# STM32H745_CM4 register map
File version: 2.5
CPU: CM4 r0p1, little endian, MPU, FPU, 4 interrupt priority bits
Registers are 32-bit, read-write, reset 0x0 unless marked. A register's access mark holds for its fields unless they carry their own. Offsets are from the block's base; [hi:lo] are bit positions; {n}, {i} and the like mark numbered series.

## DELAY_Block_SDMMC1
Base 0x52008000
Same registers: DELAY_Block_SDMMC2 0x48022800, DELAY_Block_QUADSPI 0x52006000
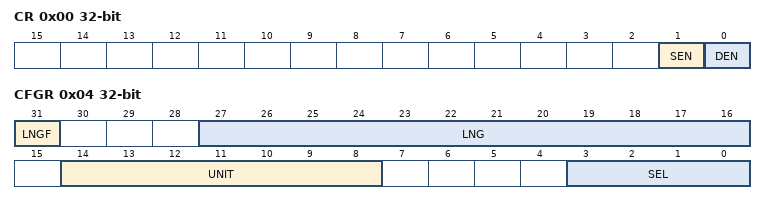
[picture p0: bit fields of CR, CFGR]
0x00 CR — DLYB control register
  [1] SEN — Sampler length enable bit
  [0] DEN — Delay block enable bit
0x04 CFGR — DLYB configuration register
  [31] LNGF — Length valid flag
  [27:16] LNG — Delay line length value
  [14:8] UNIT — Delay Defines the delay of a Unit delay cell
  [3:0] SEL — Select the phase for the Output clock

## DCMI — Digital camera interface
Base 0x48020000
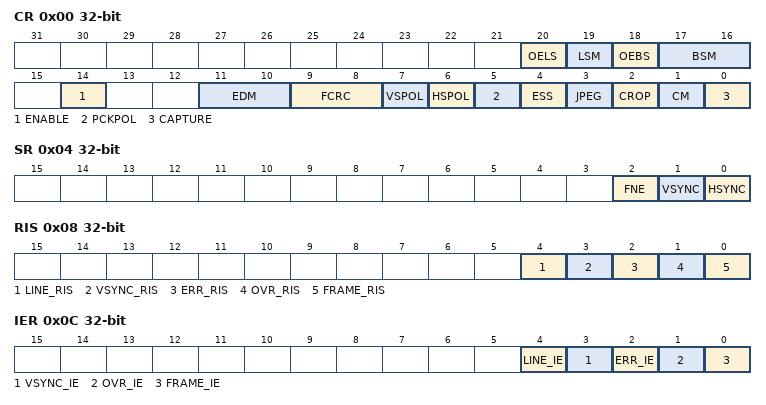
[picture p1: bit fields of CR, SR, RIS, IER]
0x00 CR — control register 1
  [20] OELS — Odd/Even Line Select (Line Select Start)
  [19] LSM — Line Select mode
  [18] OEBS — Odd/Even Byte Select (Byte Select Start)
  [17:16] BSM — Byte Select mode
  [14] ENABLE — DCMI enable
  [11:10] EDM — Extended data mode
  [9:8] FCRC — Frame capture rate control
  [7] VSPOL — Vertical synchronization polarity
  [6] HSPOL — Horizontal synchronization polarity
  [5] PCKPOL — Pixel clock polarity
  [4] ESS — Embedded synchronization select
  [3] JPEG — JPEG format
  [2] CROP — Crop feature
  [1] CM — Capture mode
  [0] CAPTURE — Capture enable
0x04 SR ro — status register
  [2] FNE — FIFO not empty
  [1] VSYNC
  [0] HSYNC
0x08 RIS ro — raw interrupt status register
  [4] LINE_RIS — Line raw interrupt status
  [3] VSYNC_RIS — VSYNC raw interrupt status
  [2] ERR_RIS — Synchronization error raw interrupt status
  [1] OVR_RIS — Overrun raw interrupt status
  [0] FRAME_RIS — Capture complete raw interrupt status
0x0C IER — interrupt enable register
  [4] LINE_IE — Line interrupt enable
  [3] VSYNC_IE — VSYNC interrupt enable
  [2] ERR_IE — Synchronization error interrupt enable
  [1] OVR_IE — Overrun interrupt enable
  [0] FRAME_IE — Capture complete interrupt enable
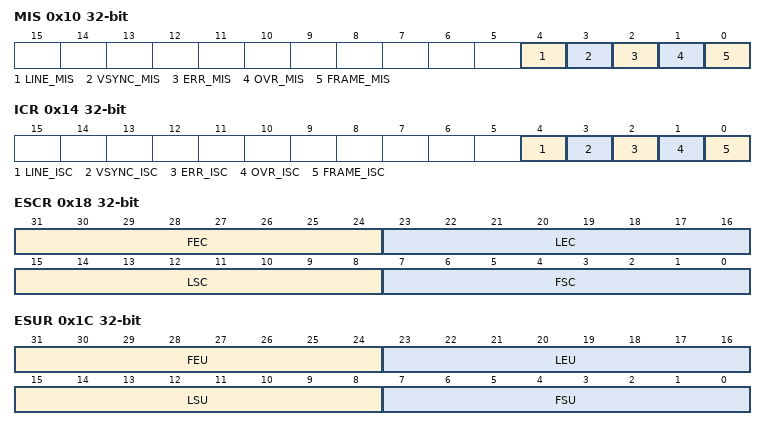
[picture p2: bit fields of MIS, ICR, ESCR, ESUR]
0x10 MIS ro — masked interrupt status register
  [4] LINE_MIS — Line masked interrupt status
  [3] VSYNC_MIS — VSYNC masked interrupt status
  [2] ERR_MIS — Synchronization error masked interrupt status
  [1] OVR_MIS — Overrun masked interrupt status
  [0] FRAME_MIS — Capture complete masked interrupt status
0x14 ICR wo — interrupt clear register
  [4] LINE_ISC — line interrupt status clear
  [3] VSYNC_ISC — Vertical synch interrupt status clear
  [2] ERR_ISC — Synchronization error interrupt status clear
  [1] OVR_ISC — Overrun interrupt status clear
  [0] FRAME_ISC — Capture complete interrupt status clear
0x18 ESCR — embedded synchronization code register
  [31:24] FEC — Frame end delimiter code
  [23:16] LEC — Line end delimiter code
  [15:8] LSC — Line start delimiter code
  [7:0] FSC — Frame start delimiter code
0x1C ESUR — embedded synchronization unmask register
  [31:24] FEU — Frame end delimiter unmask
  [23:16] LEU — Line end delimiter unmask
  [15:8] LSU — Line start delimiter unmask
  [7:0] FSU — Frame start delimiter unmask
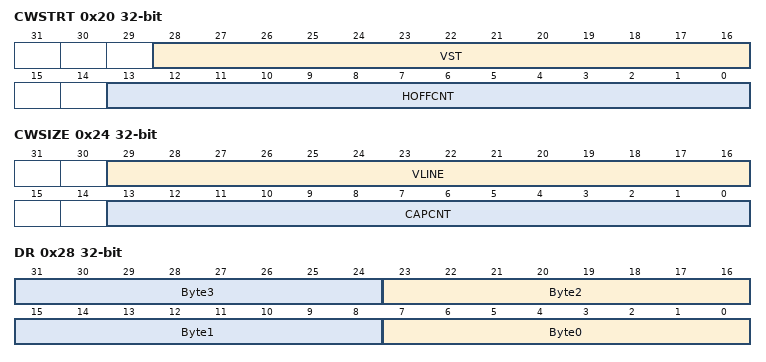
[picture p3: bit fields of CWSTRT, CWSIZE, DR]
0x20 CWSTRT — crop window start
  [28:16] VST — Vertical start line count
  [13:0] HOFFCNT — Horizontal offset count
0x24 CWSIZE — crop window size
  [29:16] VLINE — Vertical line count
  [13:0] CAPCNT — Capture count
0x28 DR ro — data register
  [8n+7:8n] Byte{n} (n=0..3) — Data byte {n}

## OTG1_HS_PWRCLK — USB 1 on the go high speed
Base 0x40040E00
Same registers: OTG2_HS_PWRCLK 0x40080E00
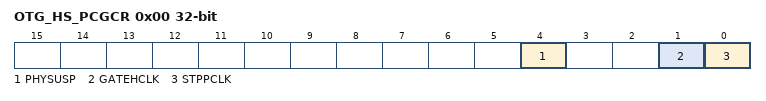
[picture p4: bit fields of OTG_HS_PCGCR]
0x00 OTG_HS_PCGCR — Power and clock gating control register
  [4] PHYSUSP — PHY suspended
  [1] GATEHCLK
  [0] STPPCLK — Stop PHY clock

## HRTIM_Master — High Resolution Timer: Master Timers
Base 0x40017400
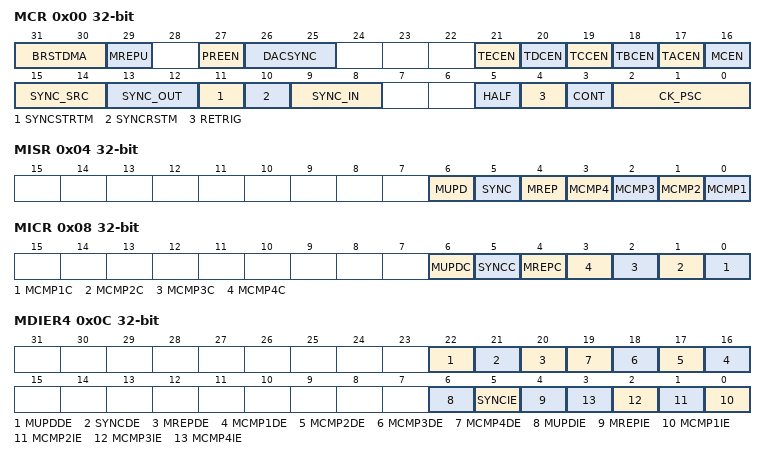
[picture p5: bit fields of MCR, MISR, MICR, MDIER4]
0x00 MCR — Master Timer Control Register
  [31:30] BRSTDMA — Burst DMA Update
  [29] MREPU — Master Timer Repetition update
  [27] PREEN — Preload enable
  [26:25] DACSYNC — AC Synchronization
  [21] TECEN — Timer E counter enable
  [20] TDCEN — Timer D counter enable
  [19] TCCEN — Timer C counter enable
  [18] TBCEN — Timer B counter enable
  [17] TACEN — Timer A counter enable
  [16] MCEN — Master Counter enable
  [15:14] SYNC_SRC — Synchronization source
  [13:12] SYNC_OUT — Synchronization output
  [11] SYNCSTRTM — Synchronization Starts Master
  [10] SYNCRSTM — Synchronization Resets Master
  [9:8] SYNC_IN — ynchronization input
  [5] HALF — Half mode enable
  [4] RETRIG — Master Re-triggerable mode
  [3] CONT — Master Continuous mode
  [2:0] CK_PSC — HRTIM Master Clock prescaler
0x04 MISR ro — Master Timer Interrupt Status Register
  [6] MUPD — Master Update Interrupt Flag
  [5] SYNC — Sync Input Interrupt Flag
  [4] MREP — Master Repetition Interrupt Flag
  [n-1] MCMP{n} (n=1..4) — Master Compare {n} Interrupt Flag
0x08 MICR wo — Master Timer Interrupt Clear Register
  [6] MUPDC — Master update Interrupt flag clear
  [5] SYNCC — Sync Input Interrupt flag clear
  [4] MREPC — Repetition Interrupt flag clear
  [n-1] MCMP{n}C (n=1..4) — Master Compare {n} Interrupt flag clear
0x0C MDIER4
  [22] MUPDDE, [21] SYNCDE, [20] MREPDE, [n+15] MCMP{n}DE (n=1..4), [6] MUPDIE, [5] SYNCIE, [4] MREPIE, [n-1] MCMP{n}IE (n=1..4)
0x10 MCNTR — Master Timer Counter Register
  [15:0] MCNT — Counter value
0x14 MPER reset 0xFFFF — Master Timer Period Register
  [15:0] MPER — Master Timer Period value
0x18 MREP — Master Timer Repetition Register
  [7:0] MREP — Master Timer Repetition counter value
0x1C MCMP1R — Master Timer Compare 1 Register
  [15:0] MCMP1 — Master Timer Compare 1 value
{0x1C+4i} MCMP{i}R (i=2..4) — Master Timer Compare {i} Register
  [15:0] MCMP{i} — Master Timer Compare {i} value

## Notices in the file
Copyright (c) 2025 STMicroelectronics.
SPDX-License-Identifier: Apache-2.0
Licensed under the Apache License, Version 2.0 (the "License");
you may not use this file except in compliance with the License.
You may obtain a copy of the License at
http://www.apache.org/licenses/LICENSE-2.0
Unless required by applicable law or agreed to in writing, software
distributed under the License is distributed on an "AS IS" BASIS,
WITHOUT WARRANTIES OR CONDITIONS OF ANY KIND, either express or implied.
See the License for the specific language governing permissions and
limitations under the License.
